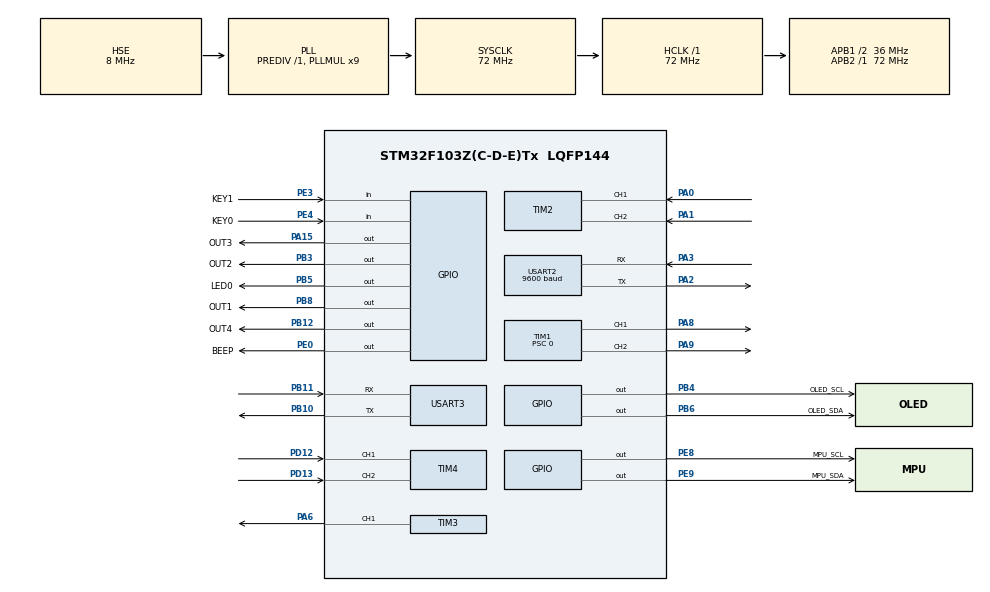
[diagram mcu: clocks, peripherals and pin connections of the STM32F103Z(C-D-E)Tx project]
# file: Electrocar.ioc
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Mcu.Family=STM32F1
Mcu.Name=STM32F103Z(C-D-E)Tx
Mcu.Package=LQFP144
NVIC.PriorityGroup=NVIC_PRIORITYGROUP_4
NVIC.TIM5_IRQn=true\:0\:0\:false\:false\:true\:true\:true\:true
NVIC.USART3_IRQn=true\:0\:0\:false\:false\:true\:true\:true\:true
OSC_IN.Mode=HSE-External-Oscillator
OSC_IN.Signal=RCC_OSC_IN
OSC_OUT.Mode=HSE-External-Oscillator
OSC_OUT.Signal=RCC_OSC_OUT
PA0-WKUP.Signal=S_TIM2_CH1_ETR
PA1.Signal=S_TIM2_CH2
PA13.Mode=Serial_Wire
PA13.Signal=SYS_JTMS-SWDIO
PA14.Mode=Serial_Wire
PA14.Signal=SYS_JTCK-SWCLK
PA15.GPIO_Label=OUT3
PA15.Signal=GPIO_Output
PA2.Mode=Asynchronous
PA2.Signal=USART2_TX
PA3.Mode=Asynchronous
PA3.Signal=USART2_RX
PA6.Signal=S_TIM3_CH1
PA8.Signal=S_TIM1_CH1
PA9.Signal=S_TIM1_CH2
PB10.Mode=Asynchronous
PB10.Signal=USART3_TX
PB11.Mode=Asynchronous
PB11.Signal=USART3_RX
PB12.GPIO_Label=OUT4
PB12.Signal=GPIO_Output
PB3.GPIO_Label=OUT2
PB3.PinState=GPIO_PIN_RESET
PB3.Signal=GPIO_Output
PB4.GPIO_Label=OLED_SCL
PB4.Signal=GPIO_Output
PB5.GPIO_Label=LED0
PB5.Signal=GPIO_Output
PB6.GPIO_Label=OLED_SDA
PB6.Signal=GPIO_Output
PB8.GPIO_Label=OUT1
PB8.PinState=GPIO_PIN_RESET
PB8.Signal=GPIO_Output
PD12.Signal=S_TIM4_CH1
PD13.Signal=S_TIM4_CH2
PE0.GPIO_Label=BEEP
PE0.PinState=GPIO_PIN_SET
PE0.Signal=GPIO_Output
PE3.GPIO_Label=KEY1
PE3.GPIO_PuPd=GPIO_PULLUP
PE3.Signal=GPIO_Input
PE4.GPIO_Label=KEY0
PE4.GPIO_PuPd=GPIO_PULLUP
PE4.Signal=GPIO_Input
PE8.GPIO_Label=MPU_SCL
PE8.Signal=GPIO_Output
PE9.GPIO_Label=MPU_SDA
PE9.Signal=GPIO_Output
ProjectManager.HeapSize=0x200
ProjectManager.StackSize=0x400
ProjectManager.TargetToolchain=MDK-ARM V5
RCC.AHBFreq_Value=72000000
RCC.APB1CLKDivider=RCC_HCLK_DIV2
RCC.APB1Freq_Value=36000000
RCC.APB1TimFreq_Value=72000000
RCC.APB2Freq_Value=72000000
RCC.APB2TimFreq_Value=72000000
RCC.HCLKFreq_Value=72000000
RCC.PLLMUL=RCC_PLL_MUL9
RCC.PLLSourceVirtual=RCC_PLLSOURCE_HSE
RCC.SYSCLKFreq_VALUE=72000000
RCC.SYSCLKSource=RCC_SYSCLKSOURCE_PLLCLK
RCC.USBFreq_Value=72000000
SH.S_TIM1_CH1.0=TIM1_CH1,PWM Generation1 CH1
SH.S_TIM1_CH2.0=TIM1_CH2,PWM Generation2 CH2
SH.S_TIM2_CH1_ETR.0=TIM2_CH1,Encoder_Interface
SH.S_TIM2_CH2.0=TIM2_CH2,Encoder_Interface
SH.S_TIM3_CH1.0=TIM3_CH1,PWM Generation1 CH1
SH.S_TIM4_CH1.0=TIM4_CH1,Encoder_Interface
SH.S_TIM4_CH2.0=TIM4_CH2,Encoder_Interface
TIM1.AutoReloadPreload=TIM_AUTORELOAD_PRELOAD_ENABLE
TIM1.Channel-PWM\ Generation1\ CH1=TIM_CHANNEL_1
TIM1.Channel-PWM\ Generation2\ CH2=TIM_CHANNEL_2
TIM1.Period=7199
TIM1.Prescaler=0
TIM2.AutoReloadPreload=TIM_AUTORELOAD_PRELOAD_ENABLE
TIM2.EncoderMode=TIM_ENCODERMODE_TI12
TIM3.AutoReloadPreload=TIM_AUTORELOAD_PRELOAD_ENABLE
TIM3.Channel-PWM\ Generation1\ CH1=TIM_CHANNEL_1
TIM3.Period=1999
TIM3.Prescaler=719
TIM4.AutoReloadPreload=TIM_AUTORELOAD_PRELOAD_ENABLE
TIM4.EncoderMode=TIM_ENCODERMODE_TI12
TIM5.AutoReloadPreload=TIM_AUTORELOAD_PRELOAD_ENABLE
TIM5.Period=7199
TIM5.Prescaler=99
USART2.BaudRate=9600
USART2.VirtualMode=VM_ASYNC
USART3.VirtualMode=VM_ASYNC
VP_TIM5_VS_ClockSourceINT.Mode=Internal
board=custom

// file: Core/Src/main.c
/* USER CODE BEGIN Header */
/**
  ******************************************************************************
  * @file           : main.c
  * @brief          : Main program body
  ******************************************************************************
  * @attention
  *
  * Copyright (c) 2022 STMicroelectronics.
  * All rights reserved.
  *
  * This software is licensed under terms that can be found in the LICENSE file
  * in the root directory of this software component.
  * If no LICENSE file comes with this software, it is provided AS-IS.
  *
  ******************************************************************************
  */
/* USER CODE END Header */
#include "main.h"
#include "tim.h"
#include "usart.h"
#include "gpio.h"

/* USER CODE BEGIN Includes */
#include "control.h"
/* USER CODE END Includes */

void SystemClock_Config(void);

int main(void)
{

  /* MCU Configuration--------------------------------------------------------*/

  /* Reset of all peripherals, Initializes the Flash interface and the Systick. */
  HAL_Init();

  /* Configure the system clock */
  SystemClock_Config();

  /* Initialize all configured peripherals */
  MX_GPIO_Init();
  MX_TIM1_Init();
  MX_TIM2_Init();
  MX_TIM3_Init();
  MX_TIM4_Init();
  MX_TIM5_Init();
  MX_USART2_UART_Init();
  MX_USART3_UART_Init();
  /* USER CODE BEGIN 2 */
	printf("init=%d\r\n",mpu_dmp_init());
	while(mpu_dmp_init());		//dmp初始化
	printf("OK！\r\n");
	ALL_Init();

  /* USER CODE END 2 */

  /* Infinite loop */
  /* USER CODE BEGIN WHILE */
  while (1)
  {

		Key_Proc();
		if(flag.carqidong2==1)
		{
			zhuhanshu2();
		}
		if(flag.carqidong==1)
		{
			zhuhanshu();
		}

    /* USER CODE END WHILE */

  }
}

void SystemClock_Config(void)
{
  RCC_OscInitTypeDef RCC_OscInitStruct = {0};
  RCC_ClkInitTypeDef RCC_ClkInitStruct = {0};

  /** Initializes the RCC Oscillators according to the specified parameters
  * in the RCC_OscInitTypeDef structure.
  */
  RCC_OscInitStruct.OscillatorType = RCC_OSCILLATORTYPE_HSE;
  RCC_OscInitStruct.HSEState = RCC_HSE_ON;
  RCC_OscInitStruct.HSEPredivValue = RCC_HSE_PREDIV_DIV1;
  RCC_OscInitStruct.HSIState = RCC_HSI_ON;
  RCC_OscInitStruct.PLL.PLLState = RCC_PLL_ON;
  RCC_OscInitStruct.PLL.PLLSource = RCC_PLLSOURCE_HSE;
  RCC_OscInitStruct.PLL.PLLMUL = RCC_PLL_MUL9;
  if (HAL_RCC_OscConfig(&RCC_OscInitStruct) != HAL_OK)
  {
    Error_Handler();
  }

  /** Initializes the CPU, AHB and APB buses clocks
  */
  RCC_ClkInitStruct.ClockType = RCC_CLOCKTYPE_HCLK|RCC_CLOCKTYPE_SYSCLK
                              |RCC_CLOCKTYPE_PCLK1|RCC_CLOCKTYPE_PCLK2;
  RCC_ClkInitStruct.SYSCLKSource = RCC_SYSCLKSOURCE_PLLCLK;
  RCC_ClkInitStruct.AHBCLKDivider = RCC_SYSCLK_DIV1;
  RCC_ClkInitStruct.APB1CLKDivider = RCC_HCLK_DIV2;
  RCC_ClkInitStruct.APB2CLKDivider = RCC_HCLK_DIV1;

  if (HAL_RCC_ClockConfig(&RCC_ClkInitStruct, FLASH_LATENCY_2) != HAL_OK)
  {
    Error_Handler();
  }
}

void Error_Handler(void)
{
  __disable_irq();
  while (1)
  {
  }
}
